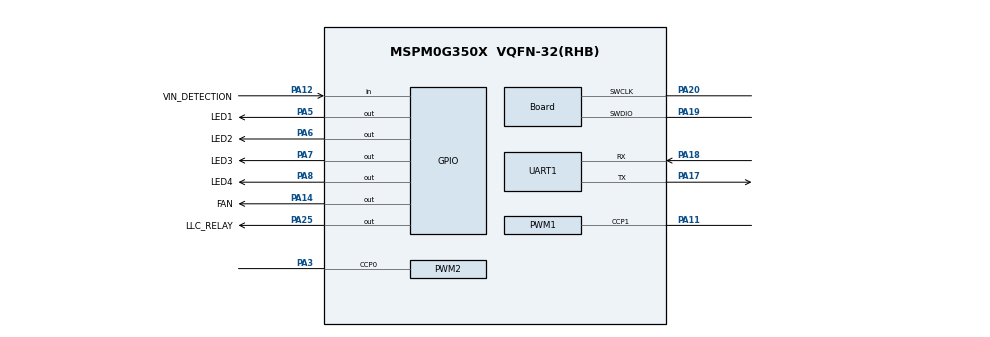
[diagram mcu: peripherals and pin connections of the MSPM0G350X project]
/**
 * @cliArgs --device "MSPM0G350X" --part "Default" --package "VQFN-32(RHB)" --product "mspm0_sdk@2.02.00.05"
 * @versions {"tool":"1.21.0+3721"}
 */

/**
 * Import the modules used in this configuration.
 */
const ADC12         = scripting.addModule("/ti/driverlib/ADC12", {}, false);
const ADC121        = ADC12.addInstance();
const ADC122        = ADC12.addInstance();
const COMP          = scripting.addModule("/ti/driverlib/COMP", {}, false);
const COMP1         = COMP.addInstance();
const GPIO          = scripting.addModule("/ti/driverlib/GPIO", {}, false);
const GPIO1         = GPIO.addInstance();
const GPIO2         = GPIO.addInstance();
const GPIO3         = GPIO.addInstance();
const GPIO4         = GPIO.addInstance();
const PWM           = scripting.addModule("/ti/driverlib/PWM", {}, false);
const PWM1          = PWM.addInstance();
const PWM2          = PWM.addInstance();
const SYSCTL        = scripting.addModule("/ti/driverlib/SYSCTL");
const TIMER         = scripting.addModule("/ti/driverlib/TIMER", {}, false);
const TIMER1        = TIMER.addInstance();
const TIMER2        = TIMER.addInstance();
const UART          = scripting.addModule("/ti/driverlib/UART", {}, false);
const UART1         = UART.addInstance();
const ProjectConfig = scripting.addModule("/ti/project_config/ProjectConfig");

/**
 * Write custom configuration values to the imported modules.
 */
ADC121.$name                      = "ADC12_0";
ADC121.samplingOperationMode      = "sequence";
ADC121.repeatMode                 = true;
ADC121.trigSrc                    = "DL_ADC12_TRIG_SRC_EVENT";
ADC121.adcMem0_name               = "TEMP";
ADC121.adcMem0avgen               = true;
ADC121.adcMem1avgen               = true;
ADC121.adcMem2_name               = "VBAT";
ADC121.endAdd                     = 3;
ADC121.adcMem3chansel             = "DL_ADC12_INPUT_CHAN_8";
ADC121.hwNumerator                = "DL_ADC12_HW_AVG_NUM_ACC_64";
ADC121.hwDenominator              = "DL_ADC12_HW_AVG_DEN_DIV_BY_64";
ADC121.subChanID                  = 1;
ADC121.adcMem2avgen               = true;
ADC121.adcMem3_name               = "IBAT";
ADC121.adcMem3avgen               = true;
ADC121.adcMem2chansel             = "DL_ADC12_INPUT_CHAN_7";
ADC121.adcMem0chansel             = "DL_ADC12_INPUT_CHAN_12";
ADC121.adcMem1chansel             = "DL_ADC12_INPUT_CHAN_1";
ADC121.startAdd                   = 1;
ADC121.adcMem1_name               = "TEMP";
ADC121.peripheral.$assign         = "ADC1";
ADC121.peripheral.adcPin8.$assign = "PA22";
ADC121.peripheral.adcPin7.$assign = "PA21";
ADC121.peripheral.adcPin1.$assign = "PA16";
ADC121.adcPin8Config.$name        = "ti_driverlib_gpio_GPIOPinGeneric5";
ADC121.adcPin7Config.$name        = "ti_driverlib_gpio_GPIOPinGeneric0";
ADC121.adcPin1Config.$name        = "ti_driverlib_gpio_GPIOPinGeneric4";

ADC122.$name                      = "ADC12_1";
ADC122.adcMem0chansel             = "DL_ADC12_INPUT_CHAN_3";
ADC122.adcMem0_name               = "VO";
ADC122.trigSrc                    = "DL_ADC12_TRIG_SRC_EVENT";
ADC122.adcMem0avgen               = true;
ADC122.hwNumerator                = "DL_ADC12_HW_AVG_NUM_ACC_64";
ADC122.hwDenominator              = "DL_ADC12_HW_AVG_DEN_DIV_BY_64";
ADC122.subChanID                  = 2;
ADC122.repeatMode                 = true;
ADC122.peripheral.$assign         = "ADC0";
ADC122.peripheral.adcPin3.$assign = "PA24";
ADC122.adcPin3Config.$name        = "ti_driverlib_gpio_GPIOPinGeneric3";

const Board                       = scripting.addModule("/ti/driverlib/Board", {}, false);
Board.peripheral.$assign          = "DEBUGSS";
Board.peripheral.swclkPin.$assign = "PA20";
Board.peripheral.swdioPin.$assign = "PA19";

COMP1.$name                          = "COMP_0";
COMP1.channelEnable                  = ["POS"];
COMP1.hysteresis                     = "DL_COMP_HYSTERESIS_30";
COMP1.vSource                        = "DL_COMP_REF_SOURCE_VDDA_DAC";
COMP1.terminalSelect                 = "DL_COMP_REF_TERMINAL_SELECT_NEG";
COMP1.controlSelect                  = "DL_COMP_DAC_CONTROL_SW";
COMP1.setDACCode0                    = 0xFF;
COMP1.peripheral.$assign             = "COMP0";
COMP1.peripheral.compPinPos0.$assign = "PA26";
COMP1.compPinPos0Config.$name        = "ti_driverlib_gpio_GPIOPinGeneric6";

GPIO1.$name                         = "RELAY_SIGNALs";
GPIO1.associatedPins[0].$name       = "LLC_RELAY";
GPIO1.associatedPins[0].pin.$assign = "PA25";

GPIO2.$name                         = "LED_SIGNALs";
GPIO2.associatedPins.create(4);
GPIO2.associatedPins[0].$name       = "LED1";
GPIO2.associatedPins[0].pin.$assign = "PA5";
GPIO2.associatedPins[1].$name       = "LED2";
GPIO2.associatedPins[1].pin.$assign = "PA6";
GPIO2.associatedPins[2].$name       = "LED3";
GPIO2.associatedPins[2].pin.$assign = "PA7";
GPIO2.associatedPins[3].$name       = "LED4";
GPIO2.associatedPins[3].pin.$assign = "PA8";

GPIO3.$name                          = "FAN_SIGNAL";
GPIO3.associatedPins[0].$name        = "FAN";
GPIO3.associatedPins[0].initialValue = "SET";
GPIO3.associatedPins[0].pin.$assign  = "PA14";

GPIO4.$name                         = "INPUT_SIGNALs";
GPIO4.associatedPins[0].$name       = "VIN_DETECTION";
GPIO4.associatedPins[0].direction   = "INPUT";
GPIO4.associatedPins[0].pin.$assign = "PA12";

PWM1.$name                           = "PWM_0";
PWM1.timerCount                      = 160;
PWM1.ccIndex                         = [1];
PWM1.ccIndexCmpl                     = [1];
PWM1.enableShadowLoad                = true;
PWM1.faultHandlerEn                  = true;
PWM1.faultSource                     = ["3"];
PWM1.COMP0Sense                      = "SENSE_HIGH";
PWM1.deadBandEn                      = true;
PWM1.dbRiseDelayTimerCount           = 32;
PWM1.dbFallDelayTimerCount           = 32;
PWM1.faultConditionDuration          = "FL_LATCH_SW_CLR";
PWM1.faultInput                      = "FI_DEPENDENT";
PWM1.faultInputEn                    = "FIEN_ENABLED";
PWM1.faultTimerCountEntry            = "FAULT_ENTRY_CTR_SUSP_COUNT";
PWM1.faultTimerCountExit             = "FAULT_EXIT_CTR_CVAE_ACTION";
PWM1.faultInputFilterEn              = true;
PWM1.faultChannel1BehaviorEntry      = "LOW";
PWM1.faultChannel1BehaviorExit       = "LOW";
PWM1.faultInputDetect                = true;
PWM1.peripheral.$assign              = "TIMA1";
PWM1.peripheral.ccp1Pin.$assign      = "PA11";
PWM1.peripheral.ccp1Pin_cmpl.$assign = "PA9";
PWM1.ccp1PinConfig.$name             = "ti_driverlib_gpio_GPIOPinGeneric2";
PWM1.PWM_CHANNEL_1.$name             = "ti_driverlib_pwm_PWMTimerCC0";
PWM1.PWM_CHANNEL_1.dutyCycle         = 50;
PWM1.PWM_CHANNEL_1.shadowUpdateMode  = "ZERO_EVT";
PWM1.ccp1Pin_cmplConfig.$name        = "ti_driverlib_gpio_GPIOPinGeneric1";

PWM2.$name                              = "FANPWM";
PWM2.ccIndex                            = [0];
PWM2.pwmMode                            = "EDGE_ALIGN_UP";
PWM2.clockDivider                       = 3;
PWM2.peripheral.$assign                 = "TIMG7";
PWM2.peripheral.ccp0Pin.$assign         = "PA3";
PWM2.PWM_CHANNEL_0.$name                = "ti_driverlib_pwm_PWMTimerCC1";
PWM2.PWM_CHANNEL_0.shadowUpdateMode     = "ZERO_EVT";
PWM2.ccp0PinConfig.direction            = scripting.forceWrite("OUTPUT");
PWM2.ccp0PinConfig.hideOutputInversion  = scripting.forceWrite(false);
PWM2.ccp0PinConfig.onlyInternalResistor = scripting.forceWrite(false);
PWM2.ccp0PinConfig.passedPeripheralType = scripting.forceWrite("Digital");
PWM2.ccp0PinConfig.$name                = "ti_driverlib_gpio_GPIOPinGeneric9";

SYSCTL.forceDefaultClkConfig = true;
SYSCTL.MCLKSource            = "HSCLK";
SYSCTL.SYSPLL_CLK0En         = true;
SYSCTL.peripheral.$assign    = "SYSCTL";

TIMER1.$name                       = "ISRTIMER";
TIMER1.timerClkPrescale            = 10;
TIMER1.timerClkDiv                 = 8;
TIMER1.timerMode                   = "PERIODIC_UP";
TIMER1.interrupts                  = ["ZERO"];
TIMER1.interruptPriority           = "0";
TIMER1.event1PublisherChannel      = 1;
TIMER1.event1ControllerInterruptEn = ["ZERO_EVENT"];
TIMER1.timerPeriod                 = "50 us";
TIMER1.event2PublisherChannel      = 2;
TIMER1.event2ControllerInterruptEn = ["ZERO_EVENT"];
TIMER1.peripheral.$assign          = "TIMG0";

TIMER2.$name              = "MACHINECYCLETIMER";
TIMER2.timerMode          = "PERIODIC_UP";
TIMER2.timerPeriod        = "200 us";
TIMER2.timerStartTimer    = true;
TIMER2.peripheral.$assign = "TIMG6";

UART1.$name                             = "UART_0";
UART1.enableFIFO                        = true;
UART1.rxFifoThreshold                   = "DL_UART_RX_FIFO_LEVEL_ONE_ENTRY";
UART1.txFifoThreshold                   = "DL_UART_TX_FIFO_LEVEL_ONE_ENTRY";
UART1.enabledDMATXTriggers              = "DL_UART_DMA_INTERRUPT_TX";
UART1.enabledInterrupts                 = ["RX"];
UART1.enableDMARX                       = false;
UART1.peripheral.$assign                = "UART1";
UART1.peripheral.rxPin.$assign          = "PA18";
UART1.peripheral.txPin.$assign          = "PA17";
UART1.txPinConfig.$name                 = "ti_driverlib_gpio_GPIOPinGeneric7";
UART1.rxPinConfig.$name                 = "ti_driverlib_gpio_GPIOPinGeneric8";
UART1.DMA_CHANNEL_TX.$name              = "DMA_CH_TX";
UART1.DMA_CHANNEL_TX.addressMode        = "b2f";
UART1.DMA_CHANNEL_TX.srcLength          = "BYTE";
UART1.DMA_CHANNEL_TX.dstLength          = "BYTE";
UART1.DMA_CHANNEL_TX.peripheral.$assign = "DMA_CH0";

ProjectConfig.deviceSpin = "MSPM0G3505";
